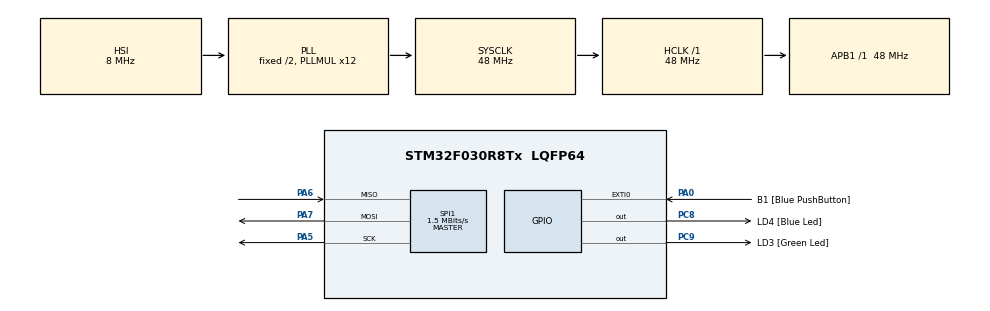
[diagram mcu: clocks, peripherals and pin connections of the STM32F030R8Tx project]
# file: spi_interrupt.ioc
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Mcu.Family=STM32F0
PA6.Mode=Full_Duplex_Master
PA7.Mode=Full_Duplex_Master
SPI1.VirtualType=VM_MASTER
PC9.GPIO_Label=LD3 [Green Led]
PA14.GPIO_Label=SWCLK
PA0.GPIO_Label=B1 [Blue PushButton]
PC8.Signal=GPIO_Output
RCC.SYSCLKSource=RCC_SYSCLKSOURCE_PLLCLK
ProjectManager.StackSize=0x400
PC8.GPIO_Label=LD4 [Blue Led]
PA13.Signal=SYS_SWDIO
ProjectManager.TargetToolchain=STM32CubeIDE
SPI1.Direction=SPI_DIRECTION_2LINES
RCC.HCLKFreq_Value=48000000
SPI1.CalculateBaudRate=1.5 MBits/s
RCC.AHBFreq_Value=48000000
PA5.Signal=SPI1_SCK
board=STM32F0308-DISCO
RCC.PLLMUL=RCC_PLL_MUL12
NVIC.SPI1_IRQn=true\:0\:0\:false\:false\:true\:true\:true
SPI1.Mode=SPI_MODE_MASTER
PA14.Mode=Serial_Wire
PA0.GPIO_ModeDefaultEXTI=GPIO_MODE_EVT_RISING
SPI1.DataSize=SPI_DATASIZE_8BIT
PA13.Mode=Serial_Wire
Mcu.Name=STM32F030R8Tx
PA13.GPIO_Label=SWDIO
PA0.Signal=GPXTI0
RCC.SYSCLKFreq_VALUE=48000000
Mcu.Package=LQFP64
PA6.Signal=SPI1_MISO
PA14.Signal=SYS_SWCLK
ProjectManager.HeapSize=0x200
RCC.APB1TimFreq_Value=48000000
PC9.Signal=GPIO_Output
RCC.APB1Freq_Value=48000000
SPI1.BaudRatePrescaler=SPI_BAUDRATEPRESCALER_32
PA5.Mode=Full_Duplex_Master
PA7.Signal=SPI1_MOSI

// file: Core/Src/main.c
/* USER CODE BEGIN Header */
/**
  ******************************************************************************
  * @file           : main.c
  * @brief          : Main program body
  ******************************************************************************
  * @attention
  *
  * <h2><center>&copy; Copyright (c) 2024 STMicroelectronics.
  * All rights reserved.</center></h2>
  *
  * This software component is licensed by ST under BSD 3-Clause license,
  * the "License"; You may not use this file except in compliance with the
  * License. You may obtain a copy of the License at:
  *                        opensource.org/licenses/BSD-3-Clause
  *
  ******************************************************************************
  */
/* USER CODE END Header */
#include "main.h"

SPI_HandleTypeDef hspi1;

/* USER CODE BEGIN PV */
uint8_t TxBuffer[10];
uint32_t TxCount=0;
/* USER CODE END PV */

void SystemClock_Config(void);
static void MX_GPIO_Init(void);
static void MX_SPI1_Init(void);

int main(void)
{

  /* MCU Configuration--------------------------------------------------------*/

  /* Reset of all peripherals, Initializes the Flash interface and the Systick. */
  HAL_Init();

  /* Configure the system clock */
  SystemClock_Config();

  /* Initialize all configured peripherals */
  MX_GPIO_Init();
  MX_SPI1_Init();

  /* Infinite loop */
  while (1)
  {
	  while(HAL_SPI_Transmit_IT(&hspi1, (uint8_t *)TxBuffer, 10)!=HAL_OK);
	  HAL_Delay(1000);
  }
}

void SystemClock_Config(void)
{
  RCC_OscInitTypeDef RCC_OscInitStruct = {0};
  RCC_ClkInitTypeDef RCC_ClkInitStruct = {0};

  /** Initializes the RCC Oscillators according to the specified parameters
  * in the RCC_OscInitTypeDef structure.
  */
  RCC_OscInitStruct.OscillatorType = RCC_OSCILLATORTYPE_HSI;
  RCC_OscInitStruct.HSIState = RCC_HSI_ON;
  RCC_OscInitStruct.HSICalibrationValue = RCC_HSICALIBRATION_DEFAULT;
  RCC_OscInitStruct.PLL.PLLState = RCC_PLL_ON;
  RCC_OscInitStruct.PLL.PLLSource = RCC_PLLSOURCE_HSI;
  RCC_OscInitStruct.PLL.PLLMUL = RCC_PLL_MUL12;
  RCC_OscInitStruct.PLL.PREDIV = RCC_PREDIV_DIV1;
  if (HAL_RCC_OscConfig(&RCC_OscInitStruct) != HAL_OK)
  {
    Error_Handler();
  }
  /** Initializes the CPU, AHB and APB buses clocks
  */
  RCC_ClkInitStruct.ClockType = RCC_CLOCKTYPE_HCLK|RCC_CLOCKTYPE_SYSCLK
                              |RCC_CLOCKTYPE_PCLK1;
  RCC_ClkInitStruct.SYSCLKSource = RCC_SYSCLKSOURCE_PLLCLK;
  RCC_ClkInitStruct.AHBCLKDivider = RCC_SYSCLK_DIV1;
  RCC_ClkInitStruct.APB1CLKDivider = RCC_HCLK_DIV1;

  if (HAL_RCC_ClockConfig(&RCC_ClkInitStruct, FLASH_LATENCY_1) != HAL_OK)
  {
    Error_Handler();
  }
}

static void MX_SPI1_Init(void)
{

  /* SPI1 parameter configuration*/
  hspi1.Instance = SPI1;
  hspi1.Init.Mode = SPI_MODE_MASTER;
  hspi1.Init.Direction = SPI_DIRECTION_2LINES;
  hspi1.Init.DataSize = SPI_DATASIZE_8BIT;
  hspi1.Init.CLKPolarity = SPI_POLARITY_LOW;
  hspi1.Init.CLKPhase = SPI_PHASE_1EDGE;
  hspi1.Init.NSS = SPI_NSS_SOFT;
  hspi1.Init.BaudRatePrescaler = SPI_BAUDRATEPRESCALER_32;
  hspi1.Init.FirstBit = SPI_FIRSTBIT_MSB;
  hspi1.Init.TIMode = SPI_TIMODE_DISABLE;
  hspi1.Init.CRCCalculation = SPI_CRCCALCULATION_DISABLE;
  hspi1.Init.CRCPolynomial = 7;
  hspi1.Init.CRCLength = SPI_CRC_LENGTH_DATASIZE;
  hspi1.Init.NSSPMode = SPI_NSS_PULSE_ENABLE;
  if (HAL_SPI_Init(&hspi1) != HAL_OK)
  {
    Error_Handler();
  }

}

static void MX_GPIO_Init(void)
{
  GPIO_InitTypeDef GPIO_InitStruct = {0};

  /* GPIO Ports Clock Enable */
  __HAL_RCC_GPIOA_CLK_ENABLE();
  __HAL_RCC_GPIOC_CLK_ENABLE();

  /*Configure GPIO pin Output Level */
  HAL_GPIO_WritePin(GPIOC, LD4_Pin|LD3_Pin, GPIO_PIN_RESET);

  /*Configure GPIO pin : B1_Pin */
  GPIO_InitStruct.Pin = B1_Pin;
  GPIO_InitStruct.Mode = GPIO_MODE_EVT_RISING;
  GPIO_InitStruct.Pull = GPIO_NOPULL;
  HAL_GPIO_Init(B1_GPIO_Port, &GPIO_InitStruct);

  /*Configure GPIO pins : LD4_Pin LD3_Pin */
  GPIO_InitStruct.Pin = LD4_Pin|LD3_Pin;
  GPIO_InitStruct.Mode = GPIO_MODE_OUTPUT_PP;
  GPIO_InitStruct.Pull = GPIO_NOPULL;
  GPIO_InitStruct.Speed = GPIO_SPEED_FREQ_LOW;
  HAL_GPIO_Init(GPIOC, &GPIO_InitStruct);

}

/* USER CODE BEGIN 4 */
void HAL_SPI_TxCpltCallback(SPI_HandleTypeDef *hspi)
{
	if(hspi->Instance == SPI1)
	{
		TxCount++;
	}
}
/* USER CODE END 4 */

void Error_Handler(void)
{
  __disable_irq();
  while (1)
  {
  }
}

/************************ (C) COPYRIGHT STMicroelectronics *****END OF FILE****/
